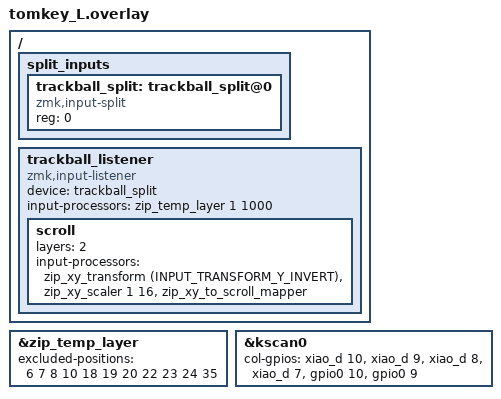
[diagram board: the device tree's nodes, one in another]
#include "tomkey.dtsi"
#include <dt-bindings/zmk/input_transform.h>
#include <input/processors.dtsi>
#include <zephyr/dt-bindings/input/input-event-codes.h>

/ {
    split_inputs {
        #address-cells = <1>;
        #size-cells = <0>;

        trackball_split: trackball_split@0 {
            compatible = "zmk,input-split";
            reg = <0>;
        };
    };

    trackball_listener: trackball_listener {
        compatible = "zmk,input-listener";
        status = "disabled";
        device = <&trackball_split>;
    };
};

&trackball_listener {
    status = "okay";
    //　input-processors = <&zip_temp_layer 1 400>; 20260319_コメント化(初期値)
    input-processors = <&zip_temp_layer 1 1000>; // 20260319_AKL抜け出し処理 追加

    scroll {
        layers = <2>;
        input-processors = <&zip_xy_transform (INPUT_TRANSFORM_Y_INVERT)>, <&zip_xy_scaler 1 16>, <&zip_xy_to_scroll_mapper>;
    };
};

// 20260319_AKL抜け出し処理 追加
&zip_temp_layer {
    excluded-positions = <
        6 // U
        7 // I
        8 // O
		10 // A
		18 // J
        19 // K
        20 // l
		22 // Z
        23 // X
        24 // C
		35 //WIN
    >;
};

&kscan0 {
        col-gpios
            = <&xiao_d 10 GPIO_ACTIVE_HIGH>
            , <&xiao_d 9 GPIO_ACTIVE_HIGH>
            , <&xiao_d 8 GPIO_ACTIVE_HIGH>
            , <&xiao_d 7 GPIO_ACTIVE_HIGH>
            , <&gpio0 10 GPIO_ACTIVE_HIGH>
            , <&gpio0 9 GPIO_ACTIVE_HIGH>
            ;
};
